# msradc_reva_me13 register map
Registers are 32-bit, read-write, no defined reset value unless marked. A register's access mark holds for its fields unless they carry their own. Offsets are from the block's base; lines under a group give offsets from that group; [hi:lo] are bit positions; {n}, {i} and the like mark numbered series; 'fields as' and 'values as' point back to an identical list; <NAME> marks a mode.

## Memory map
0x4002B000 ADC9 size 0x1000 — Magnetic Strip Reader - 9 bit ADC

## Interrupts
20 ADC9 — ADC IRQ

## ADC9 — Magnetic Strip Reader - 9 bit ADC
Base 0x4002B000
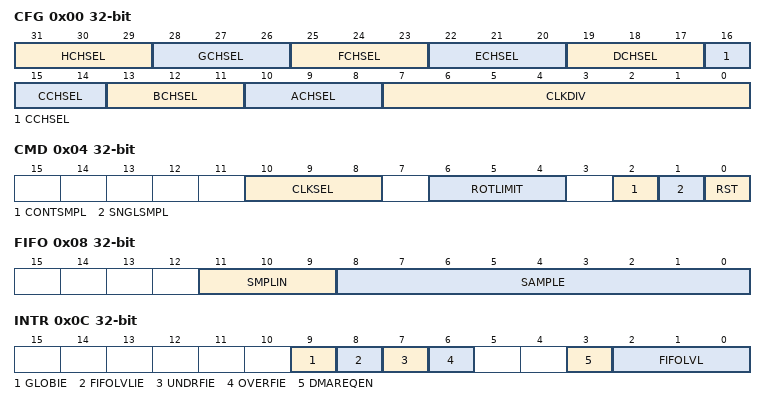
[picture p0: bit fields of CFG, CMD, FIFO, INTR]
0x00 CFG — ADC Control
  [31:29] HCHSEL — H Channel ADC Input Pin Selection.
    0=INVALID_000; {v}=IN{v-1} (v=1..6); 7=INVALID_111
  [28:26] GCHSEL — G Channel ADC Input Pin Selection.
    0=INVALID_000; {v}=IN{v-1} (v=1..6); 7=INVALID_111
  [25:23] FCHSEL — F Channel ADC Input Pin Selection.
    0=INVALID_000; {v}=IN{v-1} (v=1..6); 7=INVALID_111
  [22:20] ECHSEL — E Channel ADC Input Pin Selection.
    0=INVALID_000; {v}=IN{v-1} (v=1..6); 7=INVALID_111
  [19:17] DCHSEL — D Channel ADC Input Pin Selection.
    0=INVALID_000; {v}=IN{v-1} (v=1..6); 7=INVALID_111
  [16:14] CCHSEL — C Channel ADC Input Pin Selection.
    0=INVALID_000; {v}=IN{v-1} (v=1..6); 7=INVALID_111
  [13:11] BCHSEL — B Channel ADC Input Pin Selection.
    0=INVALID_000; {v}=IN{v-1} (v=1..6); 7=INVALID_111
  [10:8] ACHSEL — A Channel ADC Input Pin Selection.
    0=INVALID_000; {v}=IN{v-1} (v=1..6); 7=INVALID_111
  [7:0] CLKDIV — ADC Clock Divider.
0x04 CMD — MSRADC Command
  [10:8] CLKSEL — Clock Select.
    0=3_samples; 1=5_samples; 2=4_samples; 3=8_samples; 4=16_samples; 5=32_samples; 6=64_samples; 7=128_samples
  [6:4] ROTLIMIT — Rotation Limit.
    0=1_channel; {v}={v+1}_channels (v=1..7)
  [2] CONTSMPL — Continuous Sample Mode Enable.
    0=NO_CONTINUOUS_SMPL_MODE; 1=CONTINUOUS_SMPL_MODE
  [1] SNGLSMPL — Single Sample Mode.
    0=NO_EFFECT; 1=SINGLE_SMPL
  [0] RST — ADC Reset.
    0=NO_RESET; 1=RESET
0x08 FIFO — ADC FIFO
  [11:9] SMPLIN ro — ADC Sample Pin
    0=INVALID_000; {v}=IN{v-1} (v=1..6); 7=INVALID_111
  [8:0] SAMPLE ro — ADC Converted Sample Data Output
0x0C INTR — ADC Interrupt Enable Register
  [9] GLOBIE — ADC Global Interrupt Enable.
    0=DISABLED; 1=ENABLED
  [8] FIFOLVLIE — FIFO Level Interrupt Enable.
    0=DISABLED; 1=ENABLED
  [7] UNDRFIE — FIFO Underflow Interrupt Enable.
    0=DISABLED; 1=ENABLED
  [6] OVERFIE — FIFO Overflow Interrupt Enable.
    0=DISABLED; 1=ENABLED
  [3] DMAREQEN — DMA Request Enable.
    0=DISABLED; 1=ENABLED
  [2:0] FIFOLVL — Set FIFO Interrupt Level.
    {v}=at_least_{v+1} (v=0..7)
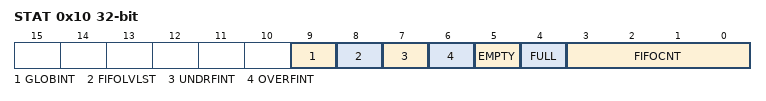
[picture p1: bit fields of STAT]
0x10 STAT — ADC Interrupt Flag Register.
  [9] GLOBINT ro — ADC Global Interrupt Status.
    0=NOT_ACTIVE; 1=ACTIVE
  [8] FIFOLVLST ro — FIFO Level Status.
    0=BELOW_LVL; 1=ABOVE_LVL
  [7] UNDRFINT ro — FIFO Underflow Status.
    0=NOT_FIFO_UNDERFLOW; 1=FIFO_UNDERFLOW
  [6] OVERFINT ro — FIFO Overflow Status.
    0=NOT_FIFO_OVERFLOW; 1=FIFO_OVERFLOW
  [5] EMPTY ro — FIFO Empty Status.
    0=FIFO_NOT_EMPTY; 1=FIFO_EMPTY
  [4] FULL ro — FIFO Full Status.
    0=FIFO_NOT_FULL; 1=FIFO_FULL
  [3:0] FIFOCNT ro — FIFO Count.
    0=FIFO_EMPTY; 1=ONE_SAMPLE; 2=TWO_SAMPLE; 3=THREE_SAMPLE; 4=FOUR_SAMPLE; 5=FIVE_SAMPLE; 6=SIX_SAMPLE; 7=SEVEN_SAMPLE; 8=EIGHT_SAMPLE
